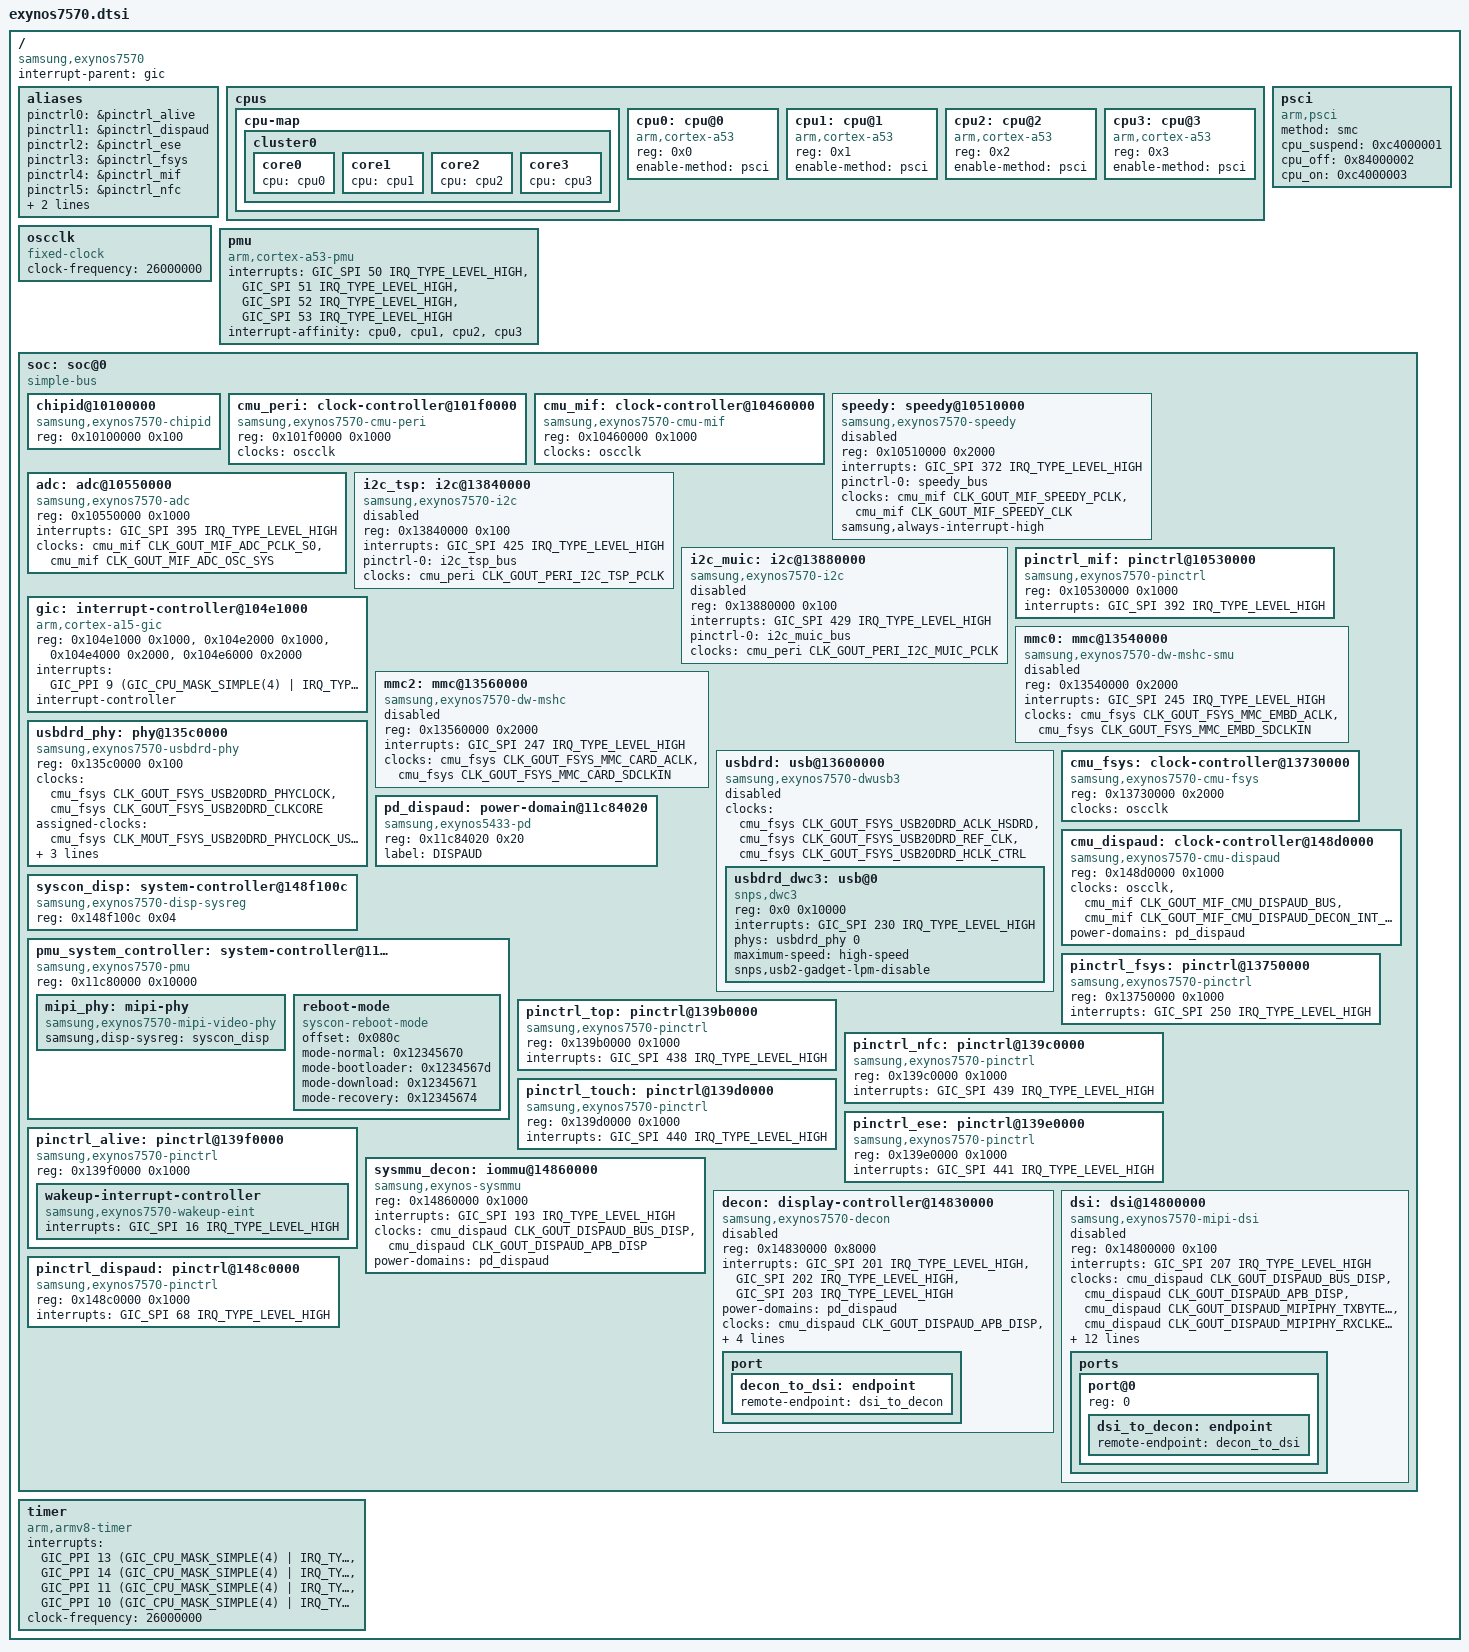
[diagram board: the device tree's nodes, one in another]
// SPDX-License-Identifier: GPL-2.0
/*
 * Samsung Exynos7570 SoC device tree source
 *
 * Copyright (c) 2016 Samsung Electronics Co., Ltd.
 */

#include <dt-bindings/clock/samsung,exynos7570-cmu.h>
#include <dt-bindings/interrupt-controller/arm-gic.h>

/ {
	compatible = "samsung,exynos7570";
	#address-cells = <2>;
	#size-cells = <1>;

	interrupt-parent = <&gic>;

	aliases {
		pinctrl0 = &pinctrl_alive;
		pinctrl1 = &pinctrl_dispaud;
		pinctrl2 = &pinctrl_ese;
		pinctrl3 = &pinctrl_fsys;
		pinctrl4 = &pinctrl_mif;
		pinctrl5 = &pinctrl_nfc;
		pinctrl6 = &pinctrl_top;
		pinctrl7 = &pinctrl_touch;
	};

	cpus {
		#address-cells = <1>;
		#size-cells = <0>;

		cpu-map {
			cluster0 {
				core0 {
					cpu = <&cpu0>;
				};
				core1 {
					cpu = <&cpu1>;
				};
				core2 {
					cpu = <&cpu2>;
				};
				core3 {
					cpu = <&cpu3>;
				};
			};
		};

		cpu0: cpu@0 {
			device_type = "cpu";
			compatible = "arm,cortex-a53";
			reg = <0x0>;
			enable-method = "psci";
		};

		cpu1: cpu@1 {
			device_type = "cpu";
			compatible = "arm,cortex-a53";
			reg = <0x1>;
			enable-method = "psci";
		};

		cpu2: cpu@2 {
			device_type = "cpu";
			compatible = "arm,cortex-a53";
			reg = <0x2>;
			enable-method = "psci";
		};

		cpu3: cpu@3 {
			device_type = "cpu";
			compatible = "arm,cortex-a53";
			reg = <0x3>;
			enable-method = "psci";
		};
	};

	oscclk: oscclk {
		compatible = "fixed-clock";
		#clock-cells = <0>;
		clock-frequency = <26000000>;
	};

	pmu {
		compatible = "arm,cortex-a53-pmu";
		interrupts = <GIC_SPI 50 IRQ_TYPE_LEVEL_HIGH>,
			     <GIC_SPI 51 IRQ_TYPE_LEVEL_HIGH>,
			     <GIC_SPI 52 IRQ_TYPE_LEVEL_HIGH>,
			     <GIC_SPI 53 IRQ_TYPE_LEVEL_HIGH>;
		interrupt-affinity = <&cpu0>, <&cpu1>, <&cpu2>, <&cpu3>;
	};

	psci {
		compatible = "arm,psci";
		method = "smc";
		cpu_suspend = <0xc4000001>;
		cpu_off = <0x84000002>;
		cpu_on = <0xc4000003>;
	};

	soc: soc@0 {
		compatible = "simple-bus";
		ranges = <0x0 0x0 0x0 0x20000000>;
		#address-cells = <1>;
		#size-cells = <1>;

		chipid@10100000 {
			compatible = "samsung,exynos7570-chipid",
				     "samsung,exynos4210-chipid";
			reg = <0x10100000 0x100>;
		};

		cmu_peri: clock-controller@101f0000 {
			compatible = "samsung,exynos7570-cmu-peri";
			reg = <0x101f0000 0x1000>;
			#clock-cells = <1>;

			clock-names = "oscclk";
			clocks = <&oscclk>;
		};

		cmu_mif: clock-controller@10460000 {
			compatible = "samsung,exynos7570-cmu-mif";
			reg = <0x10460000 0x1000>;
			#clock-cells = <1>;

			clock-names = "oscclk";
			clocks = <&oscclk>;
		};

		speedy: speedy@10510000 {
			compatible = "samsung,exynos7570-speedy";
			reg = <0x10510000 0x2000>;
			interrupts = <GIC_SPI 372 IRQ_TYPE_LEVEL_HIGH>;

			pinctrl-names = "default";
			pinctrl-0 = <&speedy_bus>;

			clock-names = "pclk", "clk";
			clocks = <&cmu_mif CLK_GOUT_MIF_SPEEDY_PCLK>,
				 <&cmu_mif CLK_GOUT_MIF_SPEEDY_CLK>;

			samsung,always-interrupt-high;

			#address-cells = <1>;
			#size-cells = <0>;

			status = "disabled";
		};

		adc: adc@10550000 {
			compatible = "samsung,exynos7570-adc";
			reg = <0x10550000 0x1000>;
			interrupts = <GIC_SPI 395 IRQ_TYPE_LEVEL_HIGH>;

			clock-names = "adc", "sclk";
			clocks = <&cmu_mif CLK_GOUT_MIF_ADC_PCLK_S0>,
				 <&cmu_mif CLK_GOUT_MIF_ADC_OSC_SYS>;

			#io-channel-cells = <1>;
		};

		i2c_tsp: i2c@13840000 {
			compatible = "samsung,exynos7570-i2c", "samsung,s3c2440-i2c";
			reg = <0x13840000 0x100>;
			interrupts = <GIC_SPI 425 IRQ_TYPE_LEVEL_HIGH>;

			pinctrl-names = "default";
			pinctrl-0 = <&i2c_tsp_bus>;

			clock-names = "i2c";
			clocks = <&cmu_peri CLK_GOUT_PERI_I2C_TSP_PCLK>;

			#address-cells = <1>;
			#size-cells = <0>;

			status = "disabled";
		};

		i2c_muic: i2c@13880000 {
			compatible = "samsung,exynos7570-i2c", "samsung,s3c2440-i2c";
			reg = <0x13880000 0x100>;
			interrupts = <GIC_SPI 429 IRQ_TYPE_LEVEL_HIGH>;

			pinctrl-names = "default";
			pinctrl-0 = <&i2c_muic_bus>;

			clock-names = "i2c";
			clocks = <&cmu_peri CLK_GOUT_PERI_I2C_MUIC_PCLK>;

			#address-cells = <1>;
			#size-cells = <0>;

			status = "disabled";
		};

		pinctrl_mif: pinctrl@10530000 {
			compatible = "samsung,exynos7570-pinctrl";
			reg = <0x10530000 0x1000>;
			interrupts = <GIC_SPI 392 IRQ_TYPE_LEVEL_HIGH>;
		};

		gic: interrupt-controller@104e1000 {
			compatible = "arm,cortex-a15-gic";
			reg = <0x104e1000 0x1000>,
			      <0x104e2000 0x1000>,
			      <0x104e4000 0x2000>,
			      <0x104e6000 0x2000>;
			interrupts = <GIC_PPI 9 (GIC_CPU_MASK_SIMPLE(4) |
						 IRQ_TYPE_LEVEL_HIGH)>;
			interrupt-controller;
			#address-cells = <0>;
			#interrupt-cells = <3>;
		};

		mmc0: mmc@13540000 {
			compatible = "samsung,exynos7570-dw-mshc-smu",
				     "samsung,exynos7870-dw-mshc-smu";
			reg = <0x13540000 0x2000>;
			interrupts = <GIC_SPI 245 IRQ_TYPE_LEVEL_HIGH>;

			clock-names = "biu", "ciu";
			clocks = <&cmu_fsys CLK_GOUT_FSYS_MMC_EMBD_ACLK>,
				 <&cmu_fsys CLK_GOUT_FSYS_MMC_EMBD_SDCLKIN>;

			#address-cells = <1>;
			#size-cells = <0>;

			status = "disabled";
		};

		mmc2: mmc@13560000 {
			compatible = "samsung,exynos7570-dw-mshc",
				     "samsung,exynos7870-dw-mshc";
			reg = <0x13560000 0x2000>;
			interrupts = <GIC_SPI 247 IRQ_TYPE_LEVEL_HIGH>;

			clock-names = "biu", "ciu";
			clocks = <&cmu_fsys CLK_GOUT_FSYS_MMC_CARD_ACLK>,
				 <&cmu_fsys CLK_GOUT_FSYS_MMC_CARD_SDCLKIN>;

			#address-cells = <1>;
			#size-cells = <0>;

			status = "disabled";
		};

		usbdrd_phy: phy@135c0000 {
			compatible = "samsung,exynos7570-usbdrd-phy",
				     "samsung,exynos7870-usbdrd-phy";
			reg = <0x135c0000 0x100>;
			#phy-cells = <1>;

			clock-names = "phy", "ref";
			clocks = <&cmu_fsys CLK_GOUT_FSYS_USB20DRD_PHYCLOCK>,
				 <&cmu_fsys CLK_GOUT_FSYS_USB20DRD_CLKCORE>;

			/* the controller needs the PHY's 60 MHz UTMI clock */
			assigned-clocks = <&cmu_fsys CLK_MOUT_FSYS_USB20DRD_PHYCLOCK_USER>;
			assigned-clock-parents = <&cmu_fsys CLK_FRAT_FSYS_USB20DRD_PHYCLOCK>;

			samsung,pmu-syscon = <&pmu_system_controller>;
		};

		usbdrd: usb@13600000 {
			compatible = "samsung,exynos7570-dwusb3",
				     "samsung,exynos7870-dwusb3";
			ranges = <0x0 0x13600000 0x10000>;
			#address-cells = <1>;
			#size-cells = <1>;

			clock-names = "bus_early", "ref", "ctrl";
			clocks = <&cmu_fsys CLK_GOUT_FSYS_USB20DRD_ACLK_HSDRD>,
				 <&cmu_fsys CLK_GOUT_FSYS_USB20DRD_REF_CLK>,
				 <&cmu_fsys CLK_GOUT_FSYS_USB20DRD_HCLK_CTRL>;

			status = "disabled";

			usbdrd_dwc3: usb@0 {
				compatible = "snps,dwc3";
				reg = <0x0 0x10000>;
				interrupts = <GIC_SPI 230 IRQ_TYPE_LEVEL_HIGH>;

				phy-names = "usb2-phy";
				phys = <&usbdrd_phy 0>;

				maximum-speed = "high-speed";
				snps,usb2-gadget-lpm-disable;
			};
		};

		cmu_fsys: clock-controller@13730000 {
			compatible = "samsung,exynos7570-cmu-fsys";
			reg = <0x13730000 0x2000>;
			#clock-cells = <1>;

			clock-names = "oscclk";
			clocks = <&oscclk>;
		};

		pd_dispaud: power-domain@11c84020 {
			compatible = "samsung,exynos5433-pd";
			reg = <0x11c84020 0x20>;
			#power-domain-cells = <0>;
			label = "DISPAUD";
		};

		cmu_dispaud: clock-controller@148d0000 {
			compatible = "samsung,exynos7570-cmu-dispaud";
			reg = <0x148d0000 0x1000>;
			#clock-cells = <1>;

			clock-names = "oscclk", "bus", "decon_vclk";
			clocks = <&oscclk>,
				 <&cmu_mif CLK_GOUT_MIF_CMU_DISPAUD_BUS>,
				 <&cmu_mif CLK_GOUT_MIF_CMU_DISPAUD_DECON_INT_VCLK>;
			power-domains = <&pd_dispaud>;
		};

		syscon_disp: system-controller@148f100c {
			compatible = "samsung,exynos7570-disp-sysreg", "syscon";
			reg = <0x148f100c 0x04>;
		};

		pmu_system_controller: system-controller@11c80000 {
			compatible = "samsung,exynos7570-pmu",
				     "samsung,exynos7-pmu", "syscon";
			reg = <0x11c80000 0x10000>;

			mipi_phy: mipi-phy {
				compatible = "samsung,exynos7570-mipi-video-phy";
				#phy-cells = <1>;

				samsung,disp-sysreg = <&syscon_disp>;
			};

			reboot-mode {
				compatible = "syscon-reboot-mode";
				offset = <0x080c>;
				mode-normal = <0x12345670>;
				mode-bootloader = <0x1234567d>;
				mode-download = <0x12345671>;
				mode-recovery = <0x12345674>;
			};
		};

		pinctrl_fsys: pinctrl@13750000 {
			compatible = "samsung,exynos7570-pinctrl";
			reg = <0x13750000 0x1000>;
			interrupts = <GIC_SPI 250 IRQ_TYPE_LEVEL_HIGH>;
		};

		pinctrl_top: pinctrl@139b0000 {
			compatible = "samsung,exynos7570-pinctrl";
			reg = <0x139b0000 0x1000>;
			interrupts = <GIC_SPI 438 IRQ_TYPE_LEVEL_HIGH>;
		};

		pinctrl_nfc: pinctrl@139c0000 {
			compatible = "samsung,exynos7570-pinctrl";
			reg = <0x139c0000 0x1000>;
			interrupts = <GIC_SPI 439 IRQ_TYPE_LEVEL_HIGH>;
		};

		pinctrl_touch: pinctrl@139d0000 {
			compatible = "samsung,exynos7570-pinctrl";
			reg = <0x139d0000 0x1000>;
			interrupts = <GIC_SPI 440 IRQ_TYPE_LEVEL_HIGH>;
		};

		pinctrl_ese: pinctrl@139e0000 {
			compatible = "samsung,exynos7570-pinctrl";
			reg = <0x139e0000 0x1000>;
			interrupts = <GIC_SPI 441 IRQ_TYPE_LEVEL_HIGH>;
		};

		pinctrl_alive: pinctrl@139f0000 {
			compatible = "samsung,exynos7570-pinctrl";
			reg = <0x139f0000 0x1000>;

			wakeup-interrupt-controller {
				compatible = "samsung,exynos7570-wakeup-eint",
					     "samsung,exynos7-wakeup-eint";
				interrupts = <GIC_SPI 16 IRQ_TYPE_LEVEL_HIGH>;
			};
		};

		sysmmu_decon: iommu@14860000 {
			compatible = "samsung,exynos-sysmmu";
			reg = <0x14860000 0x1000>;
			interrupts = <GIC_SPI 193 IRQ_TYPE_LEVEL_HIGH>;
			#iommu-cells = <0>;

			clocks = <&cmu_dispaud CLK_GOUT_DISPAUD_BUS_DISP>,
				 <&cmu_dispaud CLK_GOUT_DISPAUD_APB_DISP>;
			clock-names = "aclk", "pclk";

			power-domains = <&pd_dispaud>;
		};

		decon: display-controller@14830000 {
			compatible = "samsung,exynos7570-decon";
			reg = <0x14830000 0x8000>;
			interrupts = <GIC_SPI 201 IRQ_TYPE_LEVEL_HIGH>,
				     <GIC_SPI 202 IRQ_TYPE_LEVEL_HIGH>,
				     <GIC_SPI 203 IRQ_TYPE_LEVEL_HIGH>;
			interrupt-names = "fifo", "vsync", "lcd_sys";
			power-domains = <&pd_dispaud>;

			clocks = <&cmu_dispaud CLK_GOUT_DISPAUD_APB_DISP>,
				 <&cmu_dispaud CLK_GOUT_DISPAUD_BUS_DISP>,
				 <&cmu_dispaud CLK_DOUT_DISPAUD_DECON_VCLK>,
				 <&cmu_dispaud CLK_GOUT_DISPAUD_DECON_VCLK>;
			clock-names = "pclk_decon0", "aclk_decon0",
				      "decon0_eclk", "decon0_vclk";

			iommus = <&sysmmu_decon>;

			status = "disabled";

			port {
				decon_to_dsi: endpoint {
					remote-endpoint = <&dsi_to_decon>;
				};
			};
		};

		dsi: dsi@14800000 {
			compatible = "samsung,exynos7570-mipi-dsi";
			reg = <0x14800000 0x100>;
			interrupts = <GIC_SPI 207 IRQ_TYPE_LEVEL_HIGH>;

			clocks = <&cmu_dispaud CLK_GOUT_DISPAUD_BUS_DISP>,
				 <&cmu_dispaud CLK_GOUT_DISPAUD_APB_DISP>,
				 <&cmu_dispaud CLK_GOUT_DISPAUD_MIPIPHY_TXBYTECLKHS>,
				 <&cmu_dispaud CLK_GOUT_DISPAUD_MIPIPHY_RXCLKESC0>;
			clock-names = "bus", "pll", "byte", "esc";

			power-domains = <&pd_dispaud>;

			/* the user muxes select OSCCLK out of reset */
			assigned-clocks = <&cmu_dispaud CLK_MOUT_DISPAUD_BUS_USER>,
					  <&cmu_dispaud CLK_MOUT_DISPAUD_DECON_VCLK_USER>,
					  <&cmu_dispaud CLK_MOUT_DISPAUD_MIPIPHY_TXBYTECLKHS_USER>,
					  <&cmu_dispaud CLK_MOUT_DISPAUD_MIPIPHY_RXCLKESC0_USER>;
			assigned-clock-parents = <&cmu_mif CLK_GOUT_MIF_CMU_DISPAUD_BUS>,
						 <&cmu_mif CLK_GOUT_MIF_CMU_DISPAUD_DECON_INT_VCLK>,
						 <&cmu_dispaud CLK_FRAT_DISPAUD_MIPIPHY_TXBYTECLKHS>,
						 <&cmu_dispaud CLK_FRAT_DISPAUD_MIPIPHY_RXCLKESC0>;

			phys = <&mipi_phy 1>;
			phy-names = "dsim";

			status = "disabled";

			ports {
				#address-cells = <1>;
				#size-cells = <0>;

				port@0 {
					reg = <0>;

					dsi_to_decon: endpoint {
						remote-endpoint = <&decon_to_dsi>;
					};
				};
			};
		};

		pinctrl_dispaud: pinctrl@148c0000 {
			compatible = "samsung,exynos7570-pinctrl";
			reg = <0x148c0000 0x1000>;
			interrupts = <GIC_SPI 68 IRQ_TYPE_LEVEL_HIGH>;
		};
	};

	timer {
		compatible = "arm,armv8-timer";
		interrupts = <GIC_PPI 13 (GIC_CPU_MASK_SIMPLE(4) | IRQ_TYPE_LEVEL_LOW)>,
			     <GIC_PPI 14 (GIC_CPU_MASK_SIMPLE(4) | IRQ_TYPE_LEVEL_LOW)>,
			     <GIC_PPI 11 (GIC_CPU_MASK_SIMPLE(4) | IRQ_TYPE_LEVEL_LOW)>,
			     <GIC_PPI 10 (GIC_CPU_MASK_SIMPLE(4) | IRQ_TYPE_LEVEL_LOW)>;

		/*
		 * Stock Samsung bootloader does not configure CNTFRQ_EL0
		 */
		clock-frequency = <26000000>;
	};
};

#include "exynos7570-pinctrl.dtsi"
#include "arm/samsung/exynos-syscon-restart.dtsi"
